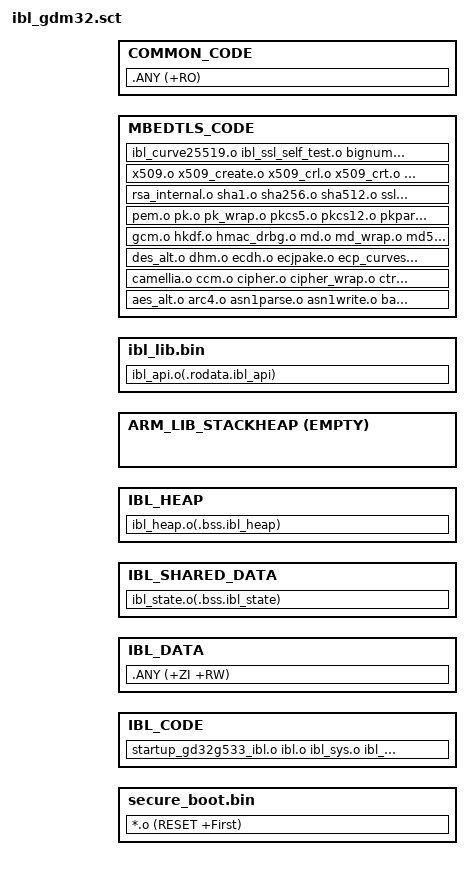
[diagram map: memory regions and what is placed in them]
#! armclang --target=arm-arm-none-eabi -march=armv8-m.main -E -xc

/*
 * Copyright (c) 2017-2018 ARM Limited. All rights reserved.
 *
 * Licensed under the Apache License, Version 2.0 (the "License");
 * you may not use this file except in compliance with the License.
 * You may obtain a copy of the License at
 *
 *     http://www.apache.org/licenses/LICENSE-2.0
 *
 * Unless required by applicable law or agreed to in writing, software
 * distributed under the License is distributed on an "AS IS" BASIS,
 * WITHOUT WARRANTIES OR CONDITIONS OF ANY KIND, either express or implied.
 * See the License for the specific language governing permissions and
 * limitations under the License.
 */
#include "..\..\IBL\ibl_region.h"

LR_CODE_1 IBL_CODE_START IBL_CODE_SIZE {
    secure_boot.bin IBL_CODE_START {
        *.o (RESET +First)
    }
    IBL_CODE +0 {
        startup_gd32g533_ibl.o ibl.o ibl_sys.o ibl_key_derive.o ibl_efuse.o 
    }

    IBL_DATA IBL_DATA_START IBL_DATA_SIZE {
        .ANY (+ZI +RW)
    }

    IBL_SHARED_DATA IBL_SHARED_DATA_START ALIGN 16 IBL_SHARED_DATA_SIZE {
        ibl_state.o(.bss.ibl_state)
    }

    IBL_HEAP IBL_SHARED_DATA_START+IBL_SHARED_DATA_SIZE ALIGN 16 IBL_HEAP_SIZE {
       ibl_heap.o(.bss.ibl_heap)
    }

    ARM_LIB_STACKHEAP +0 ALIGN 16 EMPTY IBL_MSP_STACK_SIZE {
    }

;    IBL_RECYCLE_DATA +0 ALIGN 16 {

;    }

}

LR_CODE_2 FLASH_LIB_START FLASH_LIB_SIZE {
    ibl_lib.bin +0 {
        ibl_api.o(.rodata.ibl_api)
    }

    MBEDTLS_CODE +0 ALIGN FLASH_API_ARRAY_RSVD{
        aes_alt.o /*aesni.o*/ arc4.o /*aria.o*/ asn1parse.o asn1write.o base64.o blowfish.o
        camellia.o ccm.o /*chacha20.o chachapoly.o*/ cipher.o cipher_wrap.o /*cmac.o*/ ctr_drbg.o ;certs.o 
        des_alt.o dhm.o ecdh.o ecjpake.o ecp_curves.o entropy.o entropy_poll.o error.o
        gcm.o /*havege.o*/ hkdf.o hmac_drbg.o md.o md_wrap.o /*md2.o md4.o*/ md5.o memory_buffer_alloc.o /*nist_kw.o*/ oid.o
        /*padlock.o*/ pem.o pk.o pk_wrap.o pkcs5.o /*pkcs11.o*/ pkcs12.o pkparse.o pkwrite.o platform.o platform_util.o /*poly1305.o*/
        /*ripemd160.o*/ rsa_internal.o sha1.o sha256.o sha512.o ssl_ciphersuites.o ssl_cookie.o ssl_ticket.o 
        /*threading.o timing.o version.o version_features.o*/
        x509.o x509_create.o x509_crl.o x509_crt.o x509_csr.o x509write_crt.o x509write_csr.o xtea.o 
        ibl_curve25519.o ibl_ssl_self_test.o bignum.o ecdsa.o ecp.o rsa.o
    }
    
    COMMON_CODE +0 {
        .ANY (+RO)
    }
}
